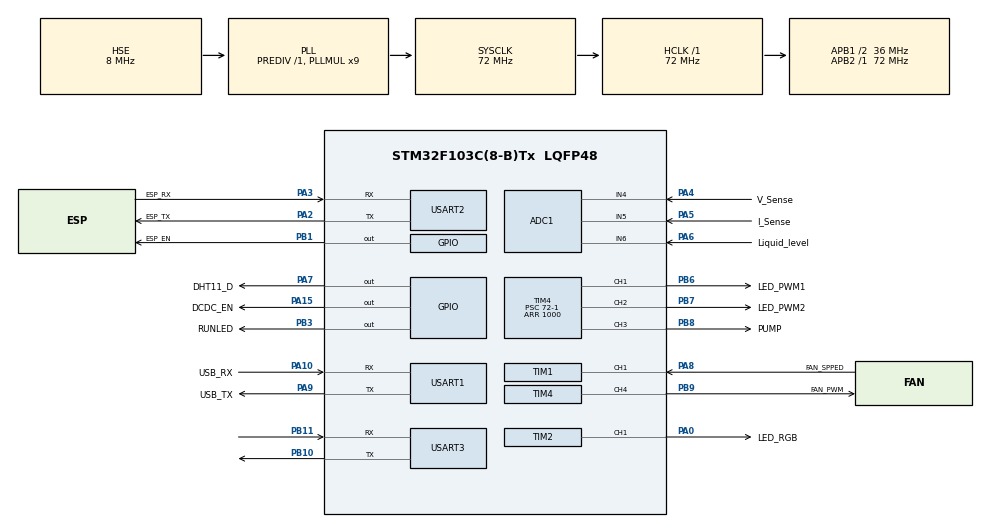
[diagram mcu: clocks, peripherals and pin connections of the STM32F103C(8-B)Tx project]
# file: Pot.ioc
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ADC1.Channel-0\#ChannelRegularConversion=ADC_CHANNEL_4
ADC1.NbrOfConversionFlag=1
ADC1.Rank-0\#ChannelRegularConversion=1
ADC1.SamplingTime-0\#ChannelRegularConversion=ADC_SAMPLETIME_1CYCLE_5
ADC1.master=1
Dma.Request0=TIM2_CH1
Dma.TIM2_CH1.0.Direction=DMA_PERIPH_TO_MEMORY
Dma.TIM2_CH1.0.Instance=DMA1_Channel5
Dma.TIM2_CH1.0.MemDataAlignment=DMA_MDATAALIGN_HALFWORD
Dma.TIM2_CH1.0.MemInc=DMA_MINC_ENABLE
Dma.TIM2_CH1.0.Mode=DMA_NORMAL
Dma.TIM2_CH1.0.PeriphDataAlignment=DMA_PDATAALIGN_HALFWORD
Dma.TIM2_CH1.0.PeriphInc=DMA_PINC_DISABLE
Dma.TIM2_CH1.0.Priority=DMA_PRIORITY_LOW
Mcu.Family=STM32F1
Mcu.Name=STM32F103C(8-B)Tx
Mcu.Package=LQFP48
NVIC.DMA1_Channel5_IRQn=true\:0\:0\:false\:false\:true\:false\:true\:true
NVIC.PriorityGroup=NVIC_PRIORITYGROUP_4
PA0-WKUP.GPIO_Label=LED_RGB
PA0-WKUP.Signal=S_TIM2_CH1_ETR
PA10.GPIO_Label=USB_RX
PA10.Mode=Asynchronous
PA10.Signal=USART1_RX
PA13.Mode=Serial_Wire
PA13.Signal=SYS_JTMS-SWDIO
PA14.Mode=Serial_Wire
PA14.Signal=SYS_JTCK-SWCLK
PA15.GPIO_Label=DCDC_EN
PA15.GPIO_PuPd=GPIO_PULLDOWN
PA15.Signal=GPIO_Output
PA2.GPIO_Label=ESP_TX
PA2.Mode=Asynchronous
PA2.Signal=USART2_TX
PA3.GPIO_Label=ESP_RX
PA3.Mode=Asynchronous
PA3.Signal=USART2_RX
PA4.GPIO_Label=V_Sense
PA4.Signal=ADCx_IN4
PA5.GPIO_Label=I_Sense
PA5.Signal=ADCx_IN5
PA6.GPIO_Label=Liquid_level
PA6.Signal=ADCx_IN6
PA7.GPIO_Label=DHT11_D
PA7.Signal=GPIO_Output
PA8.GPIO_Label=FAN_SPPED
PA8.Signal=S_TIM1_CH1
PA9.GPIO_Label=USB_TX
PA9.Mode=Asynchronous
PA9.Signal=USART1_TX
PB1.GPIO_Label=ESP_EN
PB1.Signal=GPIO_Output
PB10.Mode=Asynchronous
PB10.Signal=USART3_TX
PB11.Mode=Asynchronous
PB11.Signal=USART3_RX
PB3.GPIO_Label=RUNLED
PB3.Signal=GPIO_Output
PB6.GPIO_Label=LED_PWM1
PB6.Signal=S_TIM4_CH1
PB7.GPIO_Label=LED_PWM2
PB7.Signal=S_TIM4_CH2
PB8.GPIO_Label=PUMP
PB8.Signal=S_TIM4_CH3
PB9.GPIO_Label=FAN_PWM
PB9.Signal=S_TIM4_CH4
PD0-OSC_IN.Mode=HSE-External-Oscillator
PD0-OSC_IN.Signal=RCC_OSC_IN
PD1-OSC_OUT.Mode=HSE-External-Oscillator
PD1-OSC_OUT.Signal=RCC_OSC_OUT
ProjectManager.HeapSize=0x200
ProjectManager.StackSize=0x400
ProjectManager.TargetToolchain=MDK-ARM V5.32
RCC.ADCPresc=RCC_ADCPCLK2_DIV6
RCC.AHBFreq_Value=72000000
RCC.APB1CLKDivider=RCC_HCLK_DIV2
RCC.APB1Freq_Value=36000000
RCC.APB1TimFreq_Value=72000000
RCC.APB2Freq_Value=72000000
RCC.APB2TimFreq_Value=72000000
RCC.HCLKFreq_Value=72000000
RCC.PLLMUL=RCC_PLL_MUL9
RCC.PLLSourceVirtual=RCC_PLLSOURCE_HSE
RCC.RTCClockSelection=RCC_RTCCLKSOURCE_HSE_DIV128
RCC.SYSCLKFreq_VALUE=72000000
RCC.SYSCLKSource=RCC_SYSCLKSOURCE_PLLCLK
RCC.USBFreq_Value=72000000
SH.ADCx_IN4.0=ADC1_IN4,IN4
SH.ADCx_IN5.0=ADC1_IN5,IN5
SH.ADCx_IN6.0=ADC1_IN6,IN6
SH.S_TIM1_CH1.0=TIM1_CH1,Input_Capture1_from_TI1
SH.S_TIM2_CH1_ETR.0=TIM2_CH1,PWM Generation1 CH1
SH.S_TIM4_CH1.0=TIM4_CH1,PWM Generation1 CH1
SH.S_TIM4_CH2.0=TIM4_CH2,PWM Generation2 CH2
SH.S_TIM4_CH3.0=TIM4_CH3,PWM Generation3 CH3
SH.S_TIM4_CH4.0=TIM4_CH4,PWM Generation4 CH4
TIM1.Channel-Input_Capture1_from_TI1=TIM_CHANNEL_1
TIM1.Period=200-1
TIM1.Prescaler=72-1
TIM2.Channel-PWM\ Generation1\ CH1=TIM_CHANNEL_1
TIM4.Channel-PWM\ Generation1\ CH1=TIM_CHANNEL_1
TIM4.Channel-PWM\ Generation2\ CH2=TIM_CHANNEL_2
TIM4.Channel-PWM\ Generation3\ CH3=TIM_CHANNEL_3
TIM4.Channel-PWM\ Generation4\ CH4=TIM_CHANNEL_4
TIM4.Period=1000
TIM4.Prescaler=72-1
TIM4.Pulse-PWM\ Generation1\ CH1=10
TIM4.Pulse-PWM\ Generation2\ CH2=10
USART1.VirtualMode=VM_ASYNC
USART2.VirtualMode=VM_ASYNC
USART3.VirtualMode=VM_ASYNC
VP_RTC_VS_RTC_Activate.Mode=RTC_Enabled
VP_TIM1_VS_ClockSourceINT.Mode=Internal
board=custom

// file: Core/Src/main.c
/* USER CODE BEGIN Header */
/**
  ******************************************************************************
  * @file           : main.c
  * @brief          : Main program body
  ******************************************************************************
  * @attention
  *
  * Copyright (c) 2025 STMicroelectronics.
  * All rights reserved.
  *
  * This software is licensed under terms that can be found in the LICENSE file
  * in the root directory of this software component.
  * If no LICENSE file comes with this software, it is provided AS-IS.
  *
  ******************************************************************************
  */
/* USER CODE END Header */
#include "main.h"
#include "adc.h"
#include "dma.h"
#include "rtc.h"
#include "tim.h"
#include "usart.h"
#include "gpio.h"

void SystemClock_Config(void);

int main(void)
{

  /* MCU Configuration--------------------------------------------------------*/

  /* Reset of all peripherals, Initializes the Flash interface and the Systick. */
  HAL_Init();

  /* Configure the system clock */
  SystemClock_Config();

  /* Initialize all configured peripherals */
  MX_GPIO_Init();
  MX_DMA_Init();
  MX_RTC_Init();
  MX_TIM2_Init();
  MX_TIM4_Init();
  MX_USART1_UART_Init();
  MX_USART2_UART_Init();
  MX_TIM1_Init();
  MX_ADC1_Init();
  MX_USART3_UART_Init();
  /* USER CODE BEGIN 2 */
	HAL_TIM_PWM_Start(&htim4,TIM_CHANNEL_1);
	HAL_TIM_PWM_Start(&htim4,TIM_CHANNEL_2);
  /* USER CODE END 2 */

  /* Infinite loop */
  /* USER CODE BEGIN WHILE */
  int pwm_value = 0;
  int step = 1;
  while (1)
  {
    //pwm 0-100 999MAX 100->10%（100ma） 占空比超过50烧灯
    __HAL_TIM_SET_COMPARE(&htim4, TIM_CHANNEL_1, pwm_value);
    __HAL_TIM_SET_COMPARE(&htim4, TIM_CHANNEL_2, pwm_value);
    pwm_value += step;
    if (pwm_value >= 100 || pwm_value <= 0) {
      step = -step;
    }

    HAL_GPIO_TogglePin(RUNLED_GPIO_Port,RUNLED_Pin);
    HAL_Delay(10); // 调整延迟以控制 PWM 变化速度
    /* USER CODE END WHILE */

  }
}

void SystemClock_Config(void)
{
  RCC_OscInitTypeDef RCC_OscInitStruct = {0};
  RCC_ClkInitTypeDef RCC_ClkInitStruct = {0};
  RCC_PeriphCLKInitTypeDef PeriphClkInit = {0};

  /** Initializes the RCC Oscillators according to the specified parameters
  * in the RCC_OscInitTypeDef structure.
  */
  RCC_OscInitStruct.OscillatorType = RCC_OSCILLATORTYPE_HSE;
  RCC_OscInitStruct.HSEState = RCC_HSE_ON;
  RCC_OscInitStruct.HSEPredivValue = RCC_HSE_PREDIV_DIV1;
  RCC_OscInitStruct.HSIState = RCC_HSI_ON;
  RCC_OscInitStruct.PLL.PLLState = RCC_PLL_ON;
  RCC_OscInitStruct.PLL.PLLSource = RCC_PLLSOURCE_HSE;
  RCC_OscInitStruct.PLL.PLLMUL = RCC_PLL_MUL9;
  if (HAL_RCC_OscConfig(&RCC_OscInitStruct) != HAL_OK)
  {
    Error_Handler();
  }

  /** Initializes the CPU, AHB and APB buses clocks
  */
  RCC_ClkInitStruct.ClockType = RCC_CLOCKTYPE_HCLK|RCC_CLOCKTYPE_SYSCLK
                              |RCC_CLOCKTYPE_PCLK1|RCC_CLOCKTYPE_PCLK2;
  RCC_ClkInitStruct.SYSCLKSource = RCC_SYSCLKSOURCE_PLLCLK;
  RCC_ClkInitStruct.AHBCLKDivider = RCC_SYSCLK_DIV1;
  RCC_ClkInitStruct.APB1CLKDivider = RCC_HCLK_DIV2;
  RCC_ClkInitStruct.APB2CLKDivider = RCC_HCLK_DIV1;

  if (HAL_RCC_ClockConfig(&RCC_ClkInitStruct, FLASH_LATENCY_2) != HAL_OK)
  {
    Error_Handler();
  }
  PeriphClkInit.PeriphClockSelection = RCC_PERIPHCLK_RTC|RCC_PERIPHCLK_ADC;
  PeriphClkInit.RTCClockSelection = RCC_RTCCLKSOURCE_HSE_DIV128;
  PeriphClkInit.AdcClockSelection = RCC_ADCPCLK2_DIV6;
  if (HAL_RCCEx_PeriphCLKConfig(&PeriphClkInit) != HAL_OK)
  {
    Error_Handler();
  }
}

void Error_Handler(void)
{
  __disable_irq();
  while (1)
  {
  }
}
